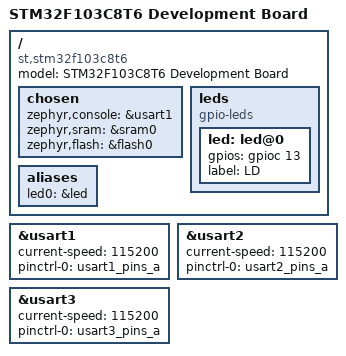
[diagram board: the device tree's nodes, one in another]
/*
 * Copyright (c) 2017, embedjournal.com
 *
 * SPDX-License-Identifier: Apache-2.0
 */

/dts-v1/;
#include <st/stm32f103Xb.dtsi>

/ {
	model = "STM32F103C8T6 Development Board";
	compatible = "st,stm32f103c8t6", "st,stm32f103rb";

	chosen {
		zephyr,console = &usart1;
		zephyr,sram = &sram0;
		zephyr,flash = &flash0;
	};

	leds {
		compatible = "gpio-leds";
		led: led@0 {
			gpios = <&gpioc 13 GPIO_INT_ACTIVE_HIGH>;
			label = "LD";
		};
	};

	aliases {
		led0 = &led;
	};
};

&usart1 {
	current-speed = <115200>;
	pinctrl-0 = <&usart1_pins_a>;
	pinctrl-names = "default";
	status = "ok";
};

&usart2 {
	current-speed = <115200>;
	pinctrl-0 = <&usart2_pins_a>;
	pinctrl-names = "default";
};

&usart3 {
	current-speed = <115200>;
	pinctrl-0 = <&usart3_pins_a>;
	pinctrl-names = "default";
};
